# RL6955_IP_SVD register map
Vendor: Realtek
Registers are 32-bit, read-write, reset 0x0 unless marked. A register's access mark holds for its fields unless they carry their own. Offsets are from the block's base; [hi:lo] are bit positions; {n}, {i} and the like mark numbered series.

## SHA_REG
Base 0x400C1000
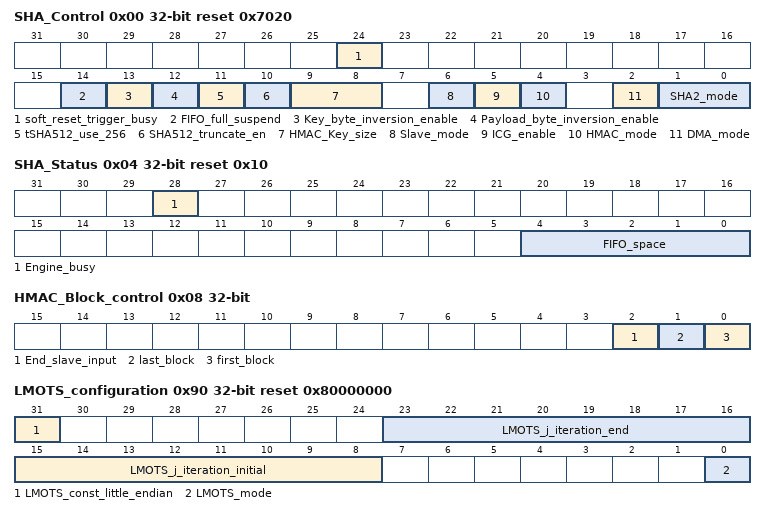
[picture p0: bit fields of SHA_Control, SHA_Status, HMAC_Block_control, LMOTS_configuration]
0x00 SHA_Control access per field reset 0x7020 — HMAC engine control register
  [24] soft_reset_trigger_busy rw — Write 1 to trigger a soft reset. All registers except the mutex register will be reset. Read the bit until 0 to determine if the soft reset is complete.
  [14] FIFO_full_suspend rw — User writes data to SHA_FIFO_in but the FIFO space is full. 0x0: accept signal is always asserted 0x1: accept signal is not asserted until FIFO space is available Note: This function is only available when Slave_mode = 0x1
  [13] Key_byte_inversion_enable rw — 0x0: use native byte order in memory 0x1: inverse byte order of read data
  [12] Payload_byte_inversion_enable rw — 0x0: use native byte order in memory 0x1: inverse byte order of read data
  [11] tSHA512_use_256 rw — Only available when config SUPPORT_TRUNCATED_SHA512 and SHA512_truncate_en= 0x1 (truncated SHA-512) 0: SHA-512/224 mode 1: SHA-512/256 mode
  [10] SHA512_truncate_en rw — Only available when config SUPPORT_TRUNCATED_SHA512 and SHA_mode = 0x3 (SHA-512) 0: normal SHA-512 1: truncated SHA-512
  [9:8] HMAC_Key_size rw — Only available when config HMAC_MODE 0x0: 128 bits 0x1: 192 bits 0x2: 256 bits
  [6] Slave_mode rw — 0: DMA mode. 1: slave mode. SW can push data by wrting FIFO Data Register in slave mode.
  [5] ICG_enable rw — Enable auto clock gating
  [4] HMAC_mode rw — Only available when config HMAC_MODE 0x0: use HASH mode. 0x1: use HMAC mode.
  [2] DMA_mode rw — 0x0: read-only mode 0x1: copy mode
  [1:0] SHA2_mode rw — 0x0: SHA-224 0x1: SHA-256 0x2: SHA-384 0x3: SHA-512
0x04 SHA_Status ro reset 0x10 — HMAC engine status register
  [28] Engine_busy — 1: engine busy
  [4:0] FIFO_space — Number of available FIFO space in byte
0x08 HMAC_Block_control access per field — HMAC engine block control register
  [2] End_slave_input rw — Avaliable when using slave mode If all input data has been completed, set this bit to 1 to start padding.
  [1] last_block rw — Indicates this operation is the last block. If set to SHA2 mode, the padding step will be executed at the end. If set to HMAC mode, the o_pad step will be executed at the end.
  [0] first_block rw — Indicates this operation is the first block. If set to SHA2 mode, the digest will be initialized automatically. If set to HMAC mode, the i_pad step will be executed first.
0x10 SHA_Digest0 reset 0xC1059ED8
  [31:0] SHA_Digest0 — Hash value 0. Reset value is SHA384 IV.
0x14 SHA_Digest1 reset 0xC1059ED8
  [31:0] SHA_Digest1 — Hash value 1. Reset value is SHA384 IV.
0x18 SHA_Digest2 reset 0x629A292A
  [31:0] SHA_Digest2 — Hash value 2. Reset value is SHA384 IV.
0x1C SHA_Digest3 reset 0x367CD507
  [31:0] SHA_Digest3 — Hash value 3. Reset value is SHA384 IV.
0x20 SHA_Digest4 reset 0x9159015A
  [31:0] SHA_Digest4 — Hash value 4. Reset value is SHA384 IV.
0x24 SHA_Digest5 reset 0x3070DD17
  [31:0] SHA_Digest5 — Hash value 5. Reset value is SHA384 IV.
0x28 SHA_Digest6 reset 0x152FECD8
  [31:0] SHA_Digest6 — Hash value 6. Reset value is SHA384 IV.
0x2C SHA_Digest7 reset 0xF70E5939
  [31:0] SHA_Digest7 — Hash value 7. Reset value is SHA384 IV.
0x30 SHA_Digest8 reset 0x67332667
  [31:0] SHA_Digest8 — Hash value 8. Reset value is SHA384 IV.
0x34 SHA_Digest9 reset 0xFFC00B31
  [31:0] SHA_Digest9 — Hash value 9. Reset value is SHA384 IV.
0x38 SHA_Digest10 reset 0x8EB44A87
  [31:0] SHA_Digest10 — Hash value 10. Reset value is SHA384 IV.
0x3C SHA_Digest11 reset 0x68581511
  [31:0] SHA_Digest11 — Hash value 11. Reset value is SHA384 IV.
0x40 SHA_Digest12 reset 0xDB0C2E0D
  [31:0] SHA_Digest12 — Hash value 12. Reset value is SHA384 IV.
0x44 SHA_Digest13 reset 0x64F98FA7
  [31:0] SHA_Digest13 — Hash value 13. Reset value is SHA384 IV.
0x48 SHA_Digest14 reset 0x47B5481D
  [31:0] SHA_Digest14 — Hash value 14. Reset value is SHA384 IV.
0x4C SHA_Digest15 reset 0xBEFA4FA4
  [31:0] SHA_Digest15 — Hash value 15. Reset value is SHA384 IV.
0x50 SHA_FIFO_IN wo — FIFO input data register for slave mode
  [31:0] SHA_FIFO_IN — Input data register for slave mode.
{0x80+4i} HASH_input_len_{i} (i=0..3) — Total input byte length register {i}
  [31:0] HASH_input_len{i} — Hash length[32*(3-{i})+31:32*(3-{i})]
0x90 LMOTS_configuration access per field reset 0x80000000
  [31] LMOTS_const_little_endian rw — Data structure of LMOTS constant registers (0x98~0xAC) 0x0 : Big-endian 0x1 : Little-endian
  [23:16] LMOTS_j_iteration_end rw — Maximum iteration index j in LMOTS process
  [15:8] LMOTS_j_iteration_initial rw — Initial iteration index j in LMOTS process
  [0] LMOTS_mode rw — The operation of LMOTS mode 0x0 : Generate public-key (KeyGen) or generate signature (SigGen) 0x1 : Verify signature Note: This register is valid only when LMOTS_enable = 0x1 This register is valid available when engine support LMOTS
0x94 LMOTS_control access per field
  [0] LMOTS_enable rw — 0x1 : enable engine to start LMOTS process Note: This register is clear automatically after LMOTS process complete.
{0x98+4i} LMOTS_constant_{i} (i=0..3)
  [31:0] LMOTS_constant_{i} — Key identifier [32*{i}+31:32*{i}]
0xA8 LMOTS_constant_4
  [31:0] LMOTS_q — Leaf index of LMOTS tree
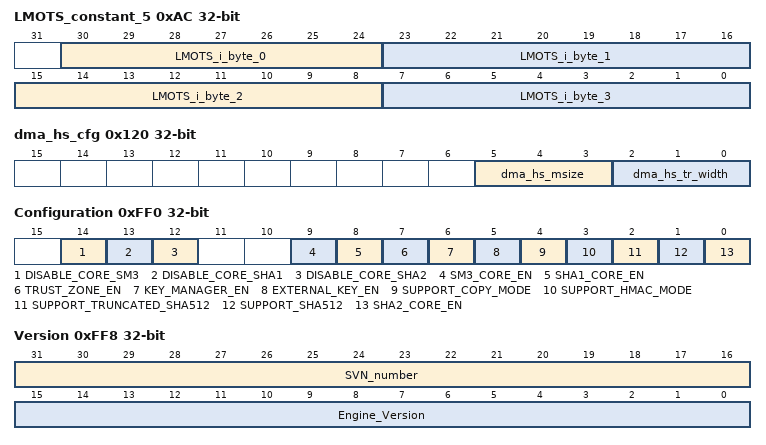
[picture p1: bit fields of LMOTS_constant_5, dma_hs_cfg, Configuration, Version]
0xAC LMOTS_constant_5
  [30:24] LMOTS_i_byte_0 — Digest byte index of LMOTS tree Note : The register is available only when LMOTS_const_little_endian = 0x0. Otherwise, it is always 0x0.
  [23:16] LMOTS_i_byte_1 — Digest byte index of LMOTS tree Note : The register is available only when LMOTS_const_little_endian = 0x0. Otherwise, it is always 0x0.
  [15:8] LMOTS_i_byte_2 — Digest byte index of LMOTS tree Note : The register is available only when LMOTS_const_little_endian = 0x1. Otherwise, it is always 0x0.
  [7:0] LMOTS_i_byte_3 — Digest byte index of LMOTS tree Note : The register is available only when LMOTS_const_little_endian = 0x1. Otherwise, it is always 0x0.
0x100 SHA256_digest_alias_0 reset 0xC1059ED8 — SHA256 Hash value register 0
  [31:0] SHA256_Digest_alias_0 — SHA256 Hash value 0. Reset value is SHA384 IV.
0x104 SHA256_digest_alias_1 reset 0x629A292A — SHA256 Hash value register 1
  [31:0] SHA256_Digest_alias_1 — SHA256 Hash value 1. Reset value is SHA384 IV.
0x108 SHA256_digest_alias_2 reset 0x9159015A — SHA256 Hash value register 2
  [31:0] SHA256_Digest_alias_2 — SHA256 Hash value 2. Reset value is SHA384 IV.
0x10C SHA256_digest_alias_3 reset 0x152FECD8 — SHA256 Hash value register 3
  [31:0] SHA256_Digest_alias_3 — SHA256 Hash value 3. Reset value is SHA384 IV.
0x110 SHA256_digest_alias_4 reset 0x67332667 — SHA256 Hash value register 4
  [31:0] SHA256_Digest_alias_4 — SHA256 Hash value 4. Reset value is SHA384 IV.
0x114 SHA256_digest_alias_5 reset 0x8EB44A87 — SHA256 Hash value register 5
  [31:0] SHA256_Digest_alias_5 — SHA256 Hash value 5. Reset value is SHA384 IV.
0x118 SHA256_digest_alias_6 reset 0xDB0C2E0D — SHA256 Hash value register 6
  [31:0] SHA256_Digest_alias_6 — SHA256 Hash value 6. Reset value is SHA384 IV.
0x11C SHA256_digest_alias_7 reset 0x47B5481D — SHA256 Hash value register 7
  [31:0] SHA256_Digest_alias_7 — SHA256 Hash value 7. Reset value is SHA384 IV.
0x120 dma_hs_cfg access per field — DMA hardware handshake configuration register
  [5:3] dma_hs_msize rw — The expected number of burst write transaction length. Please set this field to 3'b000 to avoid data loss.
  [2:0] dma_hs_tr_width rw — The expected data width of each write transaction from DMA. Since the engine uses the APB protocol, please set the field to 3'b010.
0x124 dma_hs_block_ts — DMA hardware handshake block transfer size register
  [31:0] dma_hs_block_ts — Total number of data byte for requesting DMA
0x128 dma_hs_buff_byte access per field — DMA hardware handshake buffer data byte of engine register
  [7:0] dma_hs_buff_byte rw — The register indicates number of data byte which has been processed in engine. This number will not larger than block size of engine.
0x12C dma_hs_en access per field — DMA hardware handshake enable register
  [0] dma_hs_en rw — Once the register is enabled, the engine starts to send dma_req until received wdata reaches trans_data_request.
{0x170+4i} LMOTS_sig_alias256_{i} (i=0..7) — LMOTS signature register {i}
  [31:0] LMOTS_Signature_{i} — Signature value {i} of LMOTS
0xD00 Mutex_status access per field
  [1:0] Engine_mutex_status rw — If read 0, lock mutex. If not 0, the engine is being used. 2'b01: secure domain lock mutex 2'b10: non-secure domain lock mutex Write 0 to unlock mutex
0xD04 Mutex_overwrite access per field
  [0] Engine_mutex_overwrite rw — Allows secure domain overwrite mutex 1: enable 0: disable
0xFF0 Configuration ro — Configuration information register
  [14] DISABLE_CORE_SM3 — 1: SM3 is disabled by hardware 0: SM3 is enabled
  [13] DISABLE_CORE_SHA1 — 1: SHA1 is disabled by hardware 0: SHA1 is enabled
  [12] DISABLE_CORE_SHA2 — 1: SHA2 is disabled by hardware 0: SHA2 is enabled
  [9] SM3_CORE_EN — 1: SM3 is implmented 0: SM3 is not implmented
  [8] SHA1_CORE_EN — 1: SHA1 is implmented 0: SHA1 is not implmented
  [7] TRUST_ZONE_EN — 0: disabled 1: enabled
  [6] KEY_MANAGER_EN — 0: disabled 1: enabled
  [5] EXTERNAL_KEY_EN — 0: disabled 1: enabled
  [4] SUPPORT_COPY_MODE — 0: disabled 1: enabled
  [3] SUPPORT_HMAC_MODE — 0: disabled 1: enabled
  [2] SUPPORT_TRUNCATED_SHA512 — 0: disabled 1: enabled
  [1] SUPPORT_SHA512 — 0: disabled 1: enabled
  [0] SHA2_CORE_EN — 1: SHA2 is implmented 0: SHA2 is not implmented
0xFF8 Version ro — Version number register
  [31:16] SVN_number, [15:0] Engine_Version
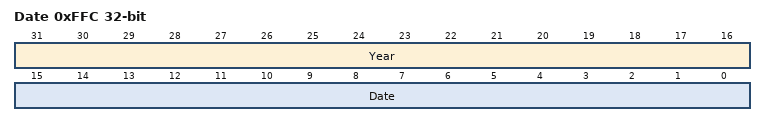
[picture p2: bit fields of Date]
0xFFC Date ro — Generated date register
  [31:16] Year, [15:0] Date
